# ATSAMR30E18A device description
Architecture: CORTEX-M0PLUS; Family: SAMR; Series: SAMR30
Registers are 32-bit, read-write, reset 0x0 unless marked. A register's access mark holds for its fields unless they carry their own. Offsets are from the block's base; [hi:lo] are bit positions; lines under a group give offsets from that group; {n}, {i} and the like mark numbered series; 'fields as' and 'values as' point back to an identical list.

## PORT — Port Module
Instances: PORT 0x40002800, PORT_IOBUS 0x60000000
{0x0+0x80*i} GROUP[{i}] (i=0..2) group
  0x00 DIR — Data Direction
    [31:0] DIR — Port Data Direction
  0x04 DIRCLR (atomic clear of DIR) — Data Direction Clear
    [31:0] DIRCLR — Port Data Direction Clear
  0x08 DIRSET (atomic set of DIR) — Data Direction Set
    [31:0] DIRSET — Port Data Direction Set
  0x0C DIRTGL (atomic toggle of DIR) — Data Direction Toggle
    [31:0] DIRTGL — Port Data Direction Toggle
  0x10 OUT — Data Output Value
    [31:0] OUT — Port Data Output Value
  0x14 OUTCLR (atomic clear of OUT) — Data Output Value Clear
    [31:0] OUTCLR — Port Data Output Value Clear
  0x18 OUTSET (atomic set of OUT) — Data Output Value Set
    [31:0] OUTSET — Port Data Output Value Set
  0x1C OUTTGL (atomic toggle of OUT) — Data Output Value Toggle
    [31:0] OUTTGL — Port Data Output Value Toggle
  0x20 IN ro — Data Input Value
    [31:0] IN — Port Data Input Value
  0x24 CTRL — Control
    [31:0] SAMPLING — Input Sampling Mode
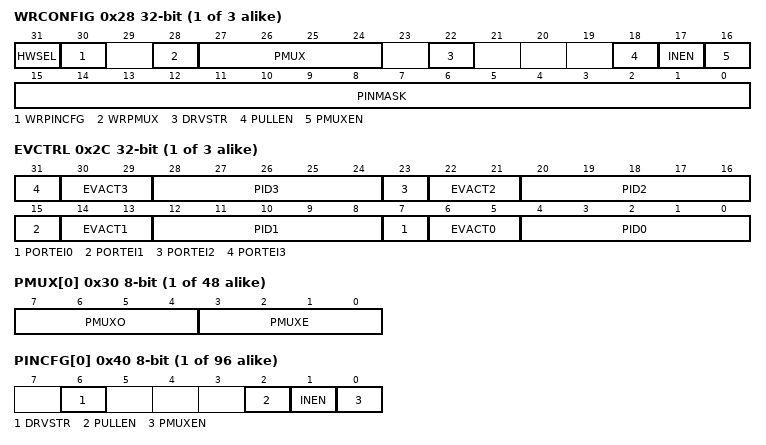
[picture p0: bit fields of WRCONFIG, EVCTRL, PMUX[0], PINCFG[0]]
  0x28 WRCONFIG wo — Write Configuration
    [31] HWSEL — Half-Word Select
    [30] WRPINCFG — Write PINCFG Registers
    [28] WRPMUX — Write PMUX Registers
    [27:24] PMUX — Peripheral Multiplexing Template
    [22] DRVSTR — Output Driver Strength Selection
    [18] PULLEN — Pull Enable
    [17] INEN — Input Enable
    [16] PMUXEN — Select Peripheral Multiplexer
    [15:0] PINMASK — Pin Mask for Multiple Pin Configuration
  0x2C EVCTRL — Event Input Control
    [8n+7] PORTEI{n} (n=0..3) — Port Event Enable Input {n}
    [8n+6:8n+5] EVACT{n} (n=0..3) — Port Event Action {n}
    [8n+4:8n] PID{n} (n=0..3) — Port Event Pin Identifier {n}
  {0x30+j} PMUX[{j}] (j=0..15) 8-bit — Peripheral Multiplexing n
    [7:4] PMUXO — Peripheral Multiplexing for Odd-Numbered Pin
      0=A (Peripheral function A selected); 1=B (Peripheral function B selected); 2=C (Peripheral function C selected); 3=D (Peripheral function D selected); 4=E (Peripheral function E selected); 5=F (Peripheral function F selected); 6=G (Peripheral function G selected); 7=H (Peripheral function H selected); 8=I (Peripheral function I selected)
    [3:0] PMUXE — Peripheral Multiplexing for Even-Numbered Pin
      values as PMUXO
  {0x40+j} PINCFG[{j}] (j=0..31) 8-bit — Pin Configuration n
    [6] DRVSTR — Output Driver Strength Selection
    [2] PULLEN — Pull Enable
    [1] INEN — Input Enable
    [0] PMUXEN — Select Peripheral Multiplexer

## RFCTRL — RF212B control module
Instances: RFCTRL 0x42003C00
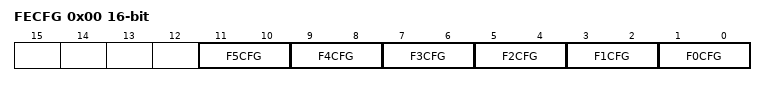
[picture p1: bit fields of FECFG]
0x00 FECFG 16-bit — Front-end control bus configuration
  [2n+1:2n] F{n}CFG (n=0..5) — Front-end control signal {n} configuration

## RSTC — Reset Controller
Instances: RSTC 0x40000800
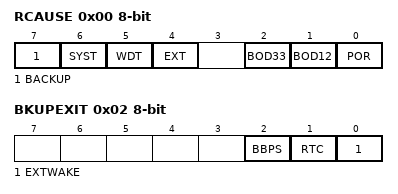
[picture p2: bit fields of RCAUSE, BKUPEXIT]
0x00 RCAUSE 8-bit ro reset not defined — Reset Cause
  [7] BACKUP — Backup Reset
  [6] SYST — System Reset Request
  [5] WDT — Watchdog Reset
  [4] EXT — External Reset
  [2] BOD33 — Brown Out 33 Detector Reset
  [1] BOD12 — Brown Out 12 Detector Reset
  [0] POR — Power On Reset
0x02 BKUPEXIT 8-bit ro reset not defined — Backup Exit Source
  [2] BBPS — Battery Backup Power Switch
  [1] RTC — Real Timer Counter Interrupt
  [0] EXTWAKE — External Wakeup
0x04 WKDBCONF 8-bit — Wakeup Debounce Configuration
  [4:0] WKDBCNT — Wakeup Debounce Counter
    0=OFF (No debouncing.Input pin is low or high level sensitive depending on its WKPOLx bit.); 1=2CK32 (Input pin shall be active for at least two 32kHz clock period.); 2=3CK32 (Input pin shall be active for at least three 32kHz clock period.); 3=32CK32 (Input pin shall be active for at least 32 32kHz clock period.); 4=512CK32 (Input pin shall be active for at least 512 32kHz clock period.); 5=4096CK32 (Input pin shall be active for at least 4096 32kHz clock period.); 6=32768CK32 (Input pin shall be active for at least 32768 32kHz clock period.)
0x08 WKPOL 16-bit — Wakeup Polarity
  [7:0] WKPOL
0x0C WKEN 16-bit — Wakeup Enable
  [7:0] WKEN
0x10 WKCAUSE 16-bit — Wakeup Cause

## Notices in the file
Copyright (c) 2018 Microchip Technology Inc.
SPDX-License-Identifier: Apache-2.0
Licensed under the Apache License, Version 2.0 (the "License");
you may not use this file except in compliance with the License.
You may obtain a copy of the License at
http://www.apache.org/licenses/LICENSE-2.0
Unless required by applicable law or agreed to in writing, software
distributed under the License is distributed on an "AS IS" BASIS,
WITHOUT WARRANTIES OR CONDITIONS OF ANY KIND, either express or implied.
See the License for the specific language governing permissions and
limitations under the License.
